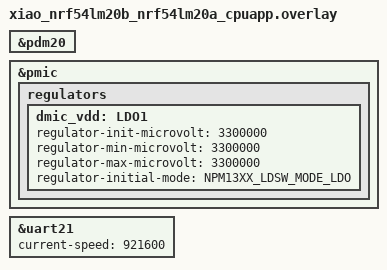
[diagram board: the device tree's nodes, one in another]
/* XIAO nRF54LM20B overlay for the DMIC recorder sample.
 * The 20B board already provides: dmic20 alias -> &pdm20 (pinctrl + clock
 * wired), the power_en regulator, and pmic_i2c (P1.18/P1.17) for the nPM1300.
 * Here we: enable pdm20; configure PMIC LDO1 as the dmic_vdd regulator in LDO
 * mode (regulated 3.3 V, not load-switch/bypass), drop regulator-boot-on so
 * the app enables it on demand via regulator_enable(); and raise the console
 * UART (uart21) to 921600 baud for the audio stream consumed by record.py.
 */

#include <zephyr/dt-bindings/regulator/npm13xx.h>

&pdm20 {
	status = "okay";
};

&pmic {
	regulators {
		dmic_vdd: LDO1 {
			/delete-property/ regulator-boot-on;
			regulator-init-microvolt = <3300000>;
			regulator-min-microvolt = <3300000>;
			regulator-max-microvolt = <3300000>;
			regulator-initial-mode = <NPM13XX_LDSW_MODE_LDO>;
		};
	};
};

&uart21 {
	current-speed = <921600>;
};
